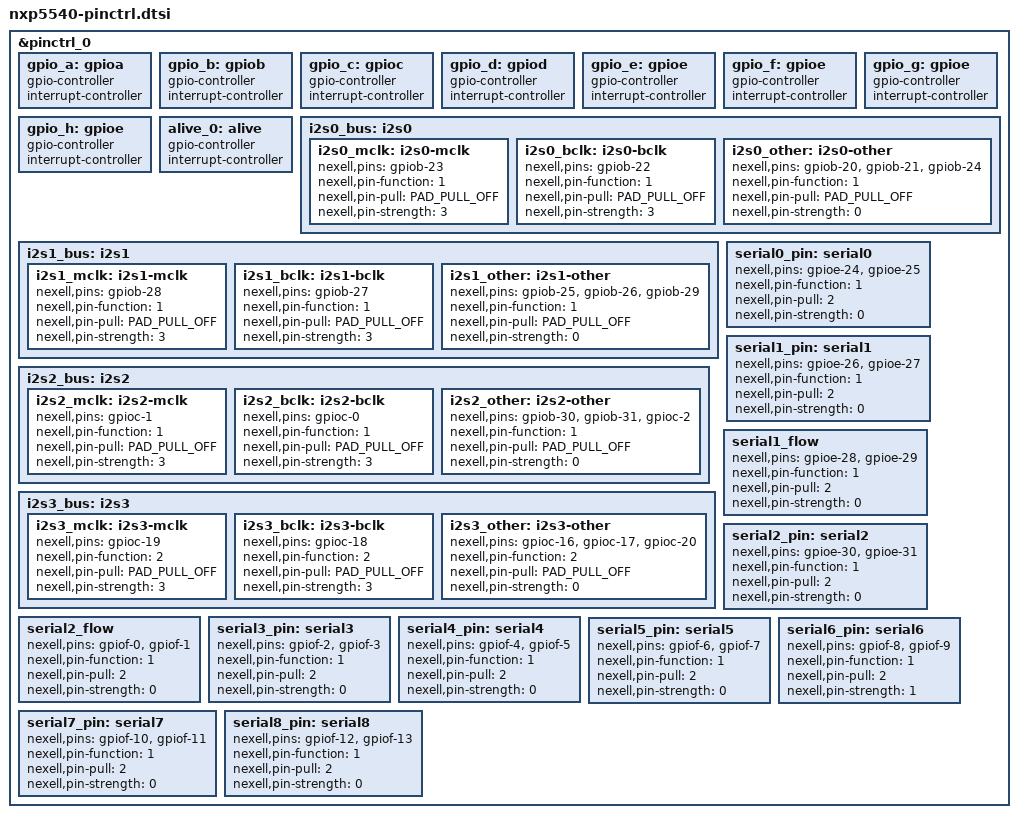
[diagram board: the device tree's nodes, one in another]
/*
 * Nexell's nxp5540 SoC pin-mux and pin-config device tree source
 *
 * Copyright (C) 2016  Nexell Co., Ltd.
 *		http://www.nexell.co.kr
 *
 * Nexell's nxp5540 SoC pin-mux and pin-config options are listed as
 * device tree nodes in this file.
 *
 * This program is free software; you can redistribute it and/or modify
 * it under the terms of the GNU General Public License version 2 as
 * published by the Free Software Foundation.
*/

&pinctrl_0 {
	gpio_a: gpioa {
		gpio-controller;
		#gpio-cells = <2>;

		interrupt-controller;
		#interrupt-cells = <2>;
	};

	gpio_b: gpiob {
		gpio-controller;
		#gpio-cells = <2>;

		interrupt-controller;
		#interrupt-cells = <2>;
	};

	gpio_c: gpioc {
		gpio-controller;
		#gpio-cells = <2>;

		interrupt-controller;
		#interrupt-cells = <2>;
	};

	gpio_d: gpiod {
		gpio-controller;
		#gpio-cells = <2>;

		interrupt-controller;
		#interrupt-cells = <2>;
	};

	gpio_e: gpioe {
		gpio-controller;
		#gpio-cells = <2>;

		interrupt-controller;
		#interrupt-cells = <2>;
	};

	gpio_f: gpioe {
		gpio-controller;
		#gpio-cells = <2>;

		interrupt-controller;
		#interrupt-cells = <2>;
	};

	gpio_g: gpioe {
		gpio-controller;
		#gpio-cells = <2>;

		interrupt-controller;
		#interrupt-cells = <2>;
	};

	gpio_h: gpioe {
		gpio-controller;
		#gpio-cells = <2>;

		interrupt-controller;
		#interrupt-cells = <2>;
	};

	alive_0: alive {
		gpio-controller;
		#gpio-cells = <2>;

		interrupt-controller;
		#interrupt-cells = <2>;
	};

	i2s0_bus:i2s0 {
		i2s0_mclk: i2s0-mclk {
			nexell,pins = "gpiob-23";
			nexell,pin-function = <1>;
			nexell,pin-pull = <PAD_PULL_OFF>;
			nexell,pin-strength = <3>;
		};

		i2s0_bclk: i2s0-bclk {
			nexell,pins = "gpiob-22";
			nexell,pin-function = <1>;
			nexell,pin-pull = <PAD_PULL_OFF>;
			nexell,pin-strength = <3>;
		};

		i2s0_other: i2s0-other {
			nexell,pins = "gpiob-20", "gpiob-21", "gpiob-24";
			nexell,pin-function = <1>;
			nexell,pin-pull = <PAD_PULL_OFF>;
			nexell,pin-strength = <0>;
		};
	};

	i2s1_bus:i2s1 {
		i2s1_mclk: i2s1-mclk {
			nexell,pins = "gpiob-28";
			nexell,pin-function = <1>;
			nexell,pin-pull = <PAD_PULL_OFF>;
			nexell,pin-strength = <3>;
		};

		i2s1_bclk: i2s1-bclk {
			nexell,pins = "gpiob-27";
			nexell,pin-function = <1>;
			nexell,pin-pull = <PAD_PULL_OFF>;
			nexell,pin-strength = <3>;
		};

		i2s1_other: i2s1-other {
			nexell,pins = "gpiob-25", "gpiob-26", "gpiob-29";
			nexell,pin-function = <1>;
			nexell,pin-pull = <PAD_PULL_OFF>;
			nexell,pin-strength = <0>;
		};
	};

	i2s2_bus:i2s2 {
		i2s2_mclk: i2s2-mclk {
			nexell,pins = "gpioc-1";
			nexell,pin-function = <1>;
			nexell,pin-pull = <PAD_PULL_OFF>;
			nexell,pin-strength = <3>;
		};

		i2s2_bclk: i2s2-bclk {
			nexell,pins = "gpioc-0";
			nexell,pin-function = <1>;
			nexell,pin-pull = <PAD_PULL_OFF>;
			nexell,pin-strength = <3>;
		};

		i2s2_other: i2s2-other {
			nexell,pins = "gpiob-30", "gpiob-31", "gpioc-2";
			nexell,pin-function = <1>;
			nexell,pin-pull = <PAD_PULL_OFF>;
			nexell,pin-strength = <0>;
		};
	};

	i2s3_bus:i2s3 {
		i2s3_mclk: i2s3-mclk {
			nexell,pins = "gpioc-19";
			nexell,pin-function = <2>;
			nexell,pin-pull = <PAD_PULL_OFF>;
			nexell,pin-strength = <3>;
		};

		i2s3_bclk: i2s3-bclk {
			nexell,pins = "gpioc-18";
			nexell,pin-function = <2>;
			nexell,pin-pull = <PAD_PULL_OFF>;
			nexell,pin-strength = <3>;
		};

		i2s3_other: i2s3-other {
			nexell,pins = "gpioc-16", "gpioc-17", "gpioc-20";
			nexell,pin-function = <2>;
			nexell,pin-pull = <PAD_PULL_OFF>;
			nexell,pin-strength = <0>;
		};
	};

	/* serial */
	serial0_pin:serial0 {
		nexell,pins = "gpioe-24", "gpioe-25";
		nexell,pin-function = <1>;
		nexell,pin-pull = <2>;
		nexell,pin-strength = <0>;
	};

	serial1_pin:serial1 {
		nexell,pins = "gpioe-26", "gpioe-27";
		nexell,pin-function = <1>;
		nexell,pin-pull = <2>;
		nexell,pin-strength = <0>;
	};

	serial1_flow:serial1_flow {
		nexell,pins = "gpioe-28", "gpioe-29";
		nexell,pin-function = <1>;
		nexell,pin-pull = <2>;
		nexell,pin-strength = <0>;
	};

	serial2_pin:serial2 {
		nexell,pins = "gpioe-30", "gpioe-31";
		nexell,pin-function = <1>;
		nexell,pin-pull = <2>;
		nexell,pin-strength = <0>;
	};

	serial2_flow:serial2_flow {
		nexell,pins = "gpiof-0", "gpiof-1";
		nexell,pin-function = <1>;
		nexell,pin-pull = <2>;
		nexell,pin-strength = <0>;
	};

	serial3_pin:serial3 {
		nexell,pins = "gpiof-2", "gpiof-3";
		nexell,pin-function = <1>;
		nexell,pin-pull = <2>;
		nexell,pin-strength = <0>;
	};

	serial4_pin:serial4 {
		nexell,pins = "gpiof-4", "gpiof-5";
		nexell,pin-function = <1>;
		nexell,pin-pull = <2>;
		nexell,pin-strength = <0>;
	};

	serial5_pin:serial5 {
		nexell,pins = "gpiof-6", "gpiof-7";
		nexell,pin-function = <1>;
		nexell,pin-pull = <2>;
		nexell,pin-strength = <0>;
	};

	serial6_pin:serial6 {
		nexell,pins = "gpiof-8", "gpiof-9";
		nexell,pin-function = <1>;
		nexell,pin-pull = <2>;
		nexell,pin-strength = <1>;
	};

	serial7_pin:serial7 {
		nexell,pins = "gpiof-10", "gpiof-11";
		nexell,pin-function = <1>;
		nexell,pin-pull = <2>;
		nexell,pin-strength = <0>;
	};

	serial8_pin:serial8 {
		nexell,pins = "gpiof-12", "gpiof-13";
		nexell,pin-function = <1>;
		nexell,pin-pull = <2>;
		nexell,pin-strength = <0>;
	};
};
